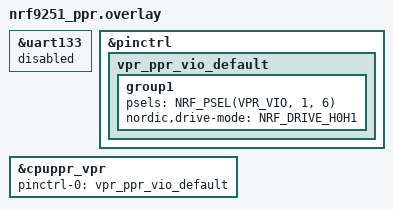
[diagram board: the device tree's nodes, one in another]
/*
 * Copyright (c) 2026 Nordic Semiconductor ASA
 *
 * SPDX-License-Identifier: LicenseRef-Nordic-5-Clause
 */

/*
 * Assign P1.06 (uart133 TX, wired to debugger UART0) to PPR (VIO 0).
 *
 * GPIO -> VIO mapping:
 *     P0.0 / P1.6  -> 0
 *     P0.1 / P1.7  -> 1
 *     P1.10        -> 2
 *     P1.11        -> 3
 */
&uart133 {
	status = "disabled";
};

&pinctrl {
	vpr_ppr_vio_default: vpr_ppr_vio_default {
		group1 {
			psels = <NRF_PSEL(VPR_VIO, 1, 6)>;
			nordic,drive-mode = <NRF_DRIVE_H0H1>;
		};
	};
};

&cpuppr_vpr {
	pinctrl-0 = <&vpr_ppr_vio_default>;
	pinctrl-names = "default";
};
